# cc13x2_cc26x2 register map
File version: 2.1
CPU: CM4 r0p1, little endian, MPU, FPU, 3 interrupt priority bits
Registers are 32-bit, read-write, reset 0x0 unless marked. A register's access mark holds for its fields unless they carry their own. Offsets are from the block's base; [hi:lo] are bit positions; {n}, {i} and the like mark numbered series; 'fields as' and 'values as' point back to an identical list.

## AUX_EVCTL — AUX Event Controller (AUX_EVCTL) assembles events originating from: AUX submodules, including ADC and comparators. AUXIO. EVENT. AON_PMCTL. AON_RTC. AON_BATMON. nto two 64-bit event buses. One is synchronized to the AUX clock and one is left unsynchronized. he subscribers to the synchronous event bus are AUX_TIMER01, AUX_SCE and AUX_EVCTL. he subscribers to the asynchronous event bus are AUX_TIMER2, AUX_ANAIF, AUX_TDC and AUX_SYSIF. UX_EVCTL uses the synchronous event bus to generate events to AON_EVENT and EVENT, as well as to AUX_SCE. AUX_SCE can poll event status registers and combine certain instructions like WEV0, WEV1 with one or two configurable events. The latter saves power when execution must stall until a condition is met.
Base 0x400C5000
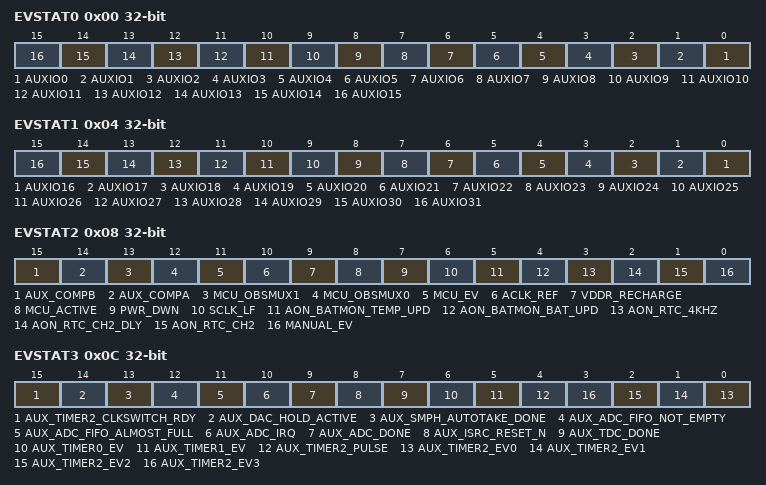
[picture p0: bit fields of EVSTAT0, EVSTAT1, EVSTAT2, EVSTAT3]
0x00 EVSTAT0 ro — Event Status 0 egister holds events 0 thru 15 of the 64-bit event bus that is synchronous to AUX clock. All events read through this register are synchronized at SCE clock rate, unless otherwise noted. The following subscribers use the asynchronous version of events in this register. AUX_TIMER2. AUX_ANAIF. AUX_TDC. AUX_SYSIF. AUX_AIODIOn. EVOBSCFG.
  [n] AUXIO{n} (n=0..15)
0x04 EVSTAT1 ro — Event Status 1 egister holds events 16 thru 31 of the 64-bit event bus that is synchronous to AUX clock. All events read through this register are synchronized at SCE clock rate, unless otherwise noted. The following subscribers use the asynchronous version of events in this register. AUX_TIMER2. AUX_ANAIF. AUX_TDC. AUX_SYSIF. AUX_AIODIOn. EVOBSCFG.
  [n-16] AUXIO{n} (n=16..31)
0x08 EVSTAT2 ro — Event Status 2 egister holds events 32 thru 47 of the 64-bit event bus that is synchronous to AUX clock. All events read through this register are synchronized at SCE clock rate, unless otherwise noted. The following subscribers use the asynchronous version of events in this register. AUX_TIMER2. AUX_ANAIF. AUX_TDC. AUX_SYSIF. AUX_AIODIOn. EVOBSCFG.
  [15] AUX_COMPB, [14] AUX_COMPA, [13] MCU_OBSMUX1, [12] MCU_OBSMUX0, [11] MCU_EV, [10] ACLK_REF, [9] VDDR_RECHARGE, [8] MCU_ACTIVE, [7] PWR_DWN, [6] SCLK_LF, [5] AON_BATMON_TEMP_UPD, [4] AON_BATMON_BAT_UPD, [3] AON_RTC_4KHZ, [2] AON_RTC_CH2_DLY, [1] AON_RTC_CH2, [0] MANUAL_EV
0x0C EVSTAT3 ro — Event Status 3 egister holds events 48 thru 63 of the 64-bit event bus that is synchronous to AUX clock. All events read through this register are synchronized at SCE clock rate, unless otherwise noted. The following subscribers use the asynchronous version of events in this register. AUX_TIMER2. AUX_ANAIF. AUX_TDC . AUX_SYSIF. AUX_AIODIOn. EVOBSCFG.
  [15] AUX_TIMER2_CLKSWITCH_RDY, [14] AUX_DAC_HOLD_ACTIVE, [13] AUX_SMPH_AUTOTAKE_DONE, [12] AUX_ADC_FIFO_NOT_EMPTY, [11] AUX_ADC_FIFO_ALMOST_FULL, [10] AUX_ADC_IRQ, [9] AUX_ADC_DONE, [8] AUX_ISRC_RESET_N, [7] AUX_TDC_DONE, [6] AUX_TIMER0_EV, [5] AUX_TIMER1_EV, [4] AUX_TIMER2_PULSE, [n] AUX_TIMER2_EV{n} (n=0..3)
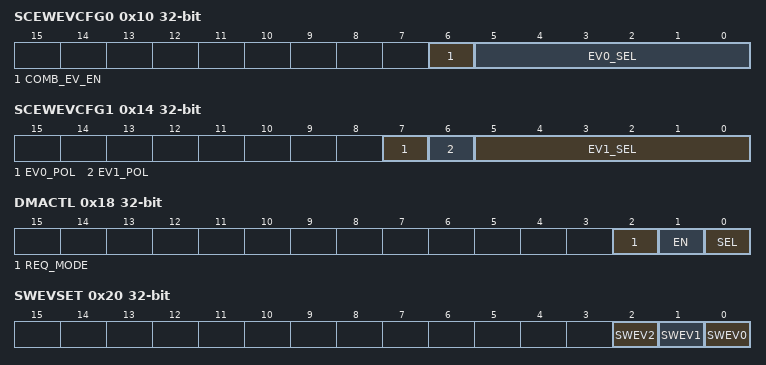
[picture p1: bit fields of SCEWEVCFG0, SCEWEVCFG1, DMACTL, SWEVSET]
0x10 SCEWEVCFG0 — Sensor Controller Engine Wait Event Configuration 0 onfiguration of this register and SCEWEVCFG1 controls bit index 7 in AUX_SCE:WUSTAT.EV_SIGNALS. This bit can be used by AUX_SCE WEV0, WEV1, BEV0 and BEV1 instructions. hen COMB_EV_EN = 0: UX_SCE:WUSTAT.EV_SIGNALS (7) = EV0_SEL event hen COMB_EV_EN = 1: UX_SCE:WUSTAT.EV_SIGNALS (7) = ( EV0_SEL event ) OR ( SCEWEVCFG1.EV1_SEL event ) it fields SCEWEVCFG1.EV0_POL and SCEWEVCFG1.EV1_POL control the polarity of selected events. vent combination is useful when there is a need to wait for a certain condition with timeout.
  [6] COMB_EV_EN, [5:0] EV0_SEL
0x14 SCEWEVCFG1 — Sensor Controller Engine Wait Event Configuration 1 ee SCEWEVCFG0 for description.
  [7] EV0_POL, [6] EV1_POL, [5:0] EV1_SEL
0x18 DMACTL — Direct Memory Access Control
  [2] REQ_MODE, [1] EN, [0] SEL
0x20 SWEVSET — Software Event Set et software event flags from AUX domain to AON and MCU domains. CPUs in MCU domain can read the event flags from EVTOAONFLAGS and clear them in EVTOAONFLAGSCLR. se of these event flags is software-defined.
  [2] SWEV2, [1] SWEV1, [0] SWEV0
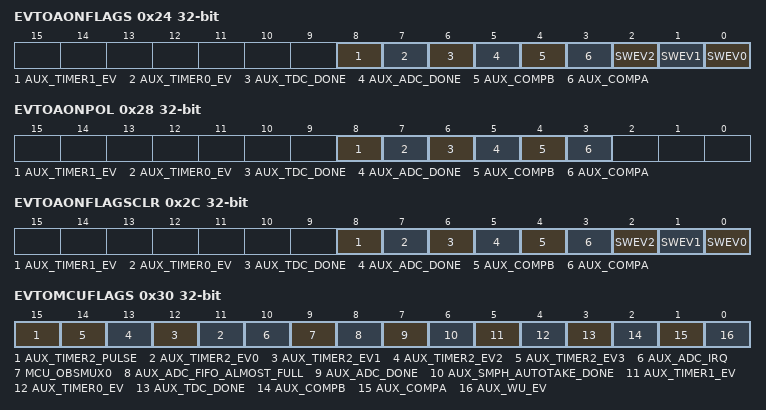
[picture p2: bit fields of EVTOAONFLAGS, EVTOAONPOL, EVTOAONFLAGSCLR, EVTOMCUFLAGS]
0x24 EVTOAONFLAGS — Events To AON Flags his register contains a collection of event flags routed to AON_EVENT. o clear an event flag, write to EVTOAONFLAGSCLR or write 0 to event flag in this register.
  [8] AUX_TIMER1_EV write-0-clears, [7] AUX_TIMER0_EV write-0-clears, [6] AUX_TDC_DONE write-0-clears, [5] AUX_ADC_DONE write-0-clears, [4] AUX_COMPB write-0-clears, [3] AUX_COMPA write-0-clears, [2] SWEV2 write-0-clears, [1] SWEV1 write-0-clears, [0] SWEV0 write-0-clears
0x28 EVTOAONPOL — Events To AON Polarity vent source polarity configuration for EVTOAONFLAGS.
  [8] AUX_TIMER1_EV, [7] AUX_TIMER0_EV, [6] AUX_TDC_DONE, [5] AUX_ADC_DONE, [4] AUX_COMPB, [3] AUX_COMPA
0x2C EVTOAONFLAGSCLR — Events To AON Clear lear event flags in EVTOAONFLAGS. n order to clear a level sensitive event flag, the event must be deasserted.
  [8] AUX_TIMER1_EV, [7] AUX_TIMER0_EV, [6] AUX_TDC_DONE, [5] AUX_ADC_DONE, [4] AUX_COMPB, [3] AUX_COMPA, [2] SWEV2, [1] SWEV1, [0] SWEV0
0x30 EVTOMCUFLAGS — Events to MCU Flags his register contains a collection of event flags routed to MCU domain. o clear an event flag, write to EVTOMCUFLAGSCLR or write 0 to event flag in this register. Follow procedure described in AUX_SYSIF:WUCLR to clear AUX_WU_EV event flag.
  [15] AUX_TIMER2_PULSE write-0-clears, [n+11] AUX_TIMER2_EV{n} write-0-clears (n=0..3), [10] AUX_ADC_IRQ write-0-clears, [9] MCU_OBSMUX0 write-0-clears, [8] AUX_ADC_FIFO_ALMOST_FULL write-0-clears, [7] AUX_ADC_DONE write-0-clears, [6] AUX_SMPH_AUTOTAKE_DONE write-0-clears, [5] AUX_TIMER1_EV write-0-clears, [4] AUX_TIMER0_EV write-0-clears, [3] AUX_TDC_DONE write-0-clears, [2] AUX_COMPB write-0-clears, [1] AUX_COMPA write-0-clears, [0] AUX_WU_EV write-0-clears
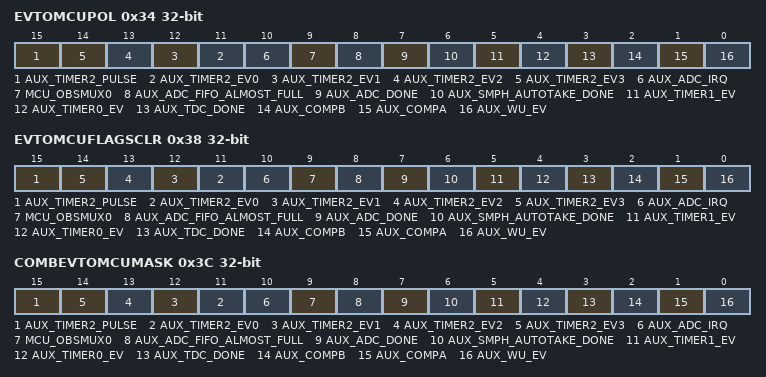
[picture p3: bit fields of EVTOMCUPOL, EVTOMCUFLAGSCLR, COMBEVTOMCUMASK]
0x34 EVTOMCUPOL — Event To MCU Polarity vent source polarity configuration for EVTOMCUFLAGS.
  [15] AUX_TIMER2_PULSE, [n+11] AUX_TIMER2_EV{n} (n=0..3), [10] AUX_ADC_IRQ, [9] MCU_OBSMUX0, [8] AUX_ADC_FIFO_ALMOST_FULL, [7] AUX_ADC_DONE, [6] AUX_SMPH_AUTOTAKE_DONE, [5] AUX_TIMER1_EV, [4] AUX_TIMER0_EV, [3] AUX_TDC_DONE, [2] AUX_COMPB, [1] AUX_COMPA, [0] AUX_WU_EV
0x38 EVTOMCUFLAGSCLR — Events To MCU Flags Clear lear event flags in EVTOMCUFLAGS. n order to clear a level sensitive event flag, the event must be deasserted.
  fields as EVTOMCUPOL
0x3C COMBEVTOMCUMASK — Combined Event To MCU Mask elect event flags in EVTOMCUFLAGS that contribute to the AUX_COMB event to EVENT and system CPU. he AUX_COMB event is high as long as one or more of the included event flags are set.
  fields as EVTOMCUPOL
0x40 EVOBSCFG — Event Observation Configuration
  [5:0] EVOBS_SEL
0x44 PROGDLY — Programmable Delay
  [15:0] VALUE
0x48 MANUAL — Manual rogrammable event.
  [0] EV
{0x4C+8i} EVSTAT{i}L ro (i=0..3) — Event Status {i} Low
  [7:0] ALIAS_EV
{0x50+8i} EVSTAT{i}H ro (i=0..3) — Event Status {i} High
  [7:0] ALIAS_EV
